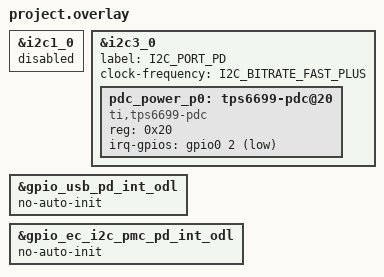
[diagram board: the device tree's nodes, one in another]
/* Copyright 2022 The ChromiumOS Authors
 * Use of this source code is governed by a BSD-style license that can be
 * found in the LICENSE file.
 */

#include "../cbi.dtsi"

#include "../orisa/cbi.dtsi"
#include "../orisa/generated.dtsi"
#include "../orisa/keyboard.dtsi"
#include "../orisa/overlay.dtsi"
#include "../orisa/power_signals.dtsi"
#include "../orisa/led_pins.dtsi"
#include "../orisa/led_policy.dtsi"

/delete-node/ &gpio_acc_int_l;
/delete-node/ &gpio_imu_int_l;
/delete-node/ &gpio_tablet_mode_l;
/delete-node/ &i2c_ec_i2c_sensor;

&i2c1_0 {
	status = "disabled";
};

/delete-node/ &pdc_power_p0;

&i2c3_0 {
	label = "I2C_PORT_PD";
	clock-frequency = <I2C_BITRATE_FAST_PLUS>;

	pdc_power_p0: tps6699-pdc@20 {
		compatible = "ti,tps6699-pdc";
		reg = <0x20>;
		irq-gpios = <&gpio0 2 GPIO_ACTIVE_LOW>;
	};
};

&gpio_usb_pd_int_odl {
	no-auto-init;
};

&gpio_ec_i2c_pmc_pd_int_odl {
	no-auto-init;
};
